# PIC32MK0128MCA028 register map
Vendor: Microchip
Registers are 32-bit, read-write, reset 0x0 unless marked. A register's access mark holds for its fields unless they carry their own. Addresses are absolute, and some are shared; only a register's first bit layout is shown; [hi:lo] are bit positions; {n}, {i} and the like mark numbered series.

## UART1
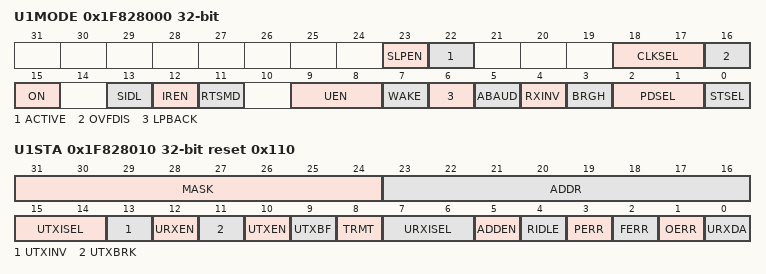
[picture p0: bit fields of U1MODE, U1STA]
0x1F828000 U1MODE
  [23] SLPEN, [22] ACTIVE, [18:17] CLKSEL, [16] OVFDIS, [15] ON, [13] SIDL, [12] IREN, [11] RTSMD, [9:8] UEN, [7] WAKE, [6] LPBACK, [5] ABAUD, [4] RXINV, [3] BRGH, [2:1] PDSEL, [0] STSEL
0x1F828010 U1STA reset 0x110
  [31:24] MASK
  [23:16] ADDR
  [15:14] UTXISEL
  [13] UTXINV
  [12] URXEN
  [11] UTXBRK
  [10] UTXEN
  [9] UTXBF ro
  [8] TRMT ro
  [7:6] URXISEL
  [5] ADDEN
  [4] RIDLE ro
  [3] PERR ro
  [2] FERR ro
  [1] OERR — (can only be cleared)
  [0] URXDA ro
0x1F828020 U1TXREG
  [8:0] U1TXREG
0x1F828030 U1RXREG ro
  [8:0] U1RXREG
0x1F828040 U1BRG
  [19:0] BRG

## UART2
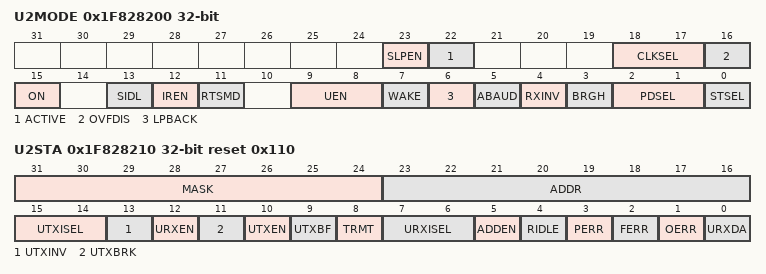
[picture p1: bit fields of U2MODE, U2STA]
0x1F828200 U2MODE
  [23] SLPEN, [22] ACTIVE, [18:17] CLKSEL, [16] OVFDIS, [15] ON, [13] SIDL, [12] IREN, [11] RTSMD, [9:8] UEN, [7] WAKE, [6] LPBACK, [5] ABAUD, [4] RXINV, [3] BRGH, [2:1] PDSEL, [0] STSEL
0x1F828210 U2STA reset 0x110
  [31:24] MASK
  [23:16] ADDR
  [15:14] UTXISEL
  [13] UTXINV
  [12] URXEN
  [11] UTXBRK
  [10] UTXEN
  [9] UTXBF ro
  [8] TRMT ro
  [7:6] URXISEL
  [5] ADDEN
  [4] RIDLE ro
  [3] PERR ro
  [2] FERR ro
  [1] OERR — (can only be cleared)
  [0] URXDA ro
0x1F828220 U2TXREG
  [8:0] U2TXREG
0x1F828230 U2RXREG ro
  [8:0] U2RXREG
0x1F828240 U2BRG
  [19:0] BRG

## MCPWMMODULE
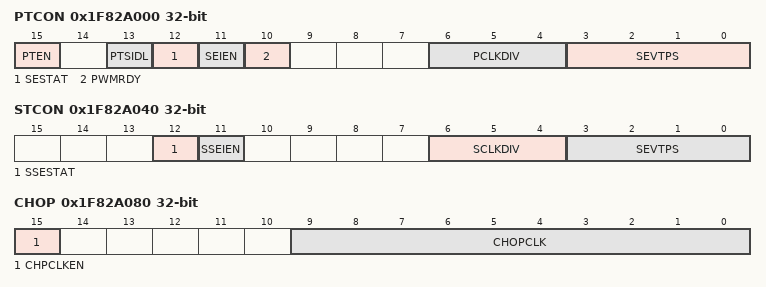
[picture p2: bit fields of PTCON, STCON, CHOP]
0x1F82A000 PTCON
  [15] PTEN, [13] PTSIDL, [12] SESTAT, [11] SEIEN, [10] PWMRDY, [6:4] PCLKDIV, [3:0] SEVTPS
0x1F82A010 PTPER
  [15:0] PTPER
0x1F82A020 SEVTCMP
  [15:0] SEVTCMP
0x1F82A030 PMTMR
  [15:0] PMTMR
0x1F82A040 STCON
  [12] SSESTAT, [11] SSEIEN, [6:4] SCLKDIV, [3:0] SEVTPS
0x1F82A050 STPER
  [15:0] STPER
0x1F82A060 SSEVTCMP
  [15:0] SSEVTCMP
0x1F82A070 SMTMR
  [15:0] SMTMR
0x1F82A080 CHOP
  [15] CHPCLKEN, [9:0] CHOPCLK
0x1F82A090 PWMKEY
  [15:0] PWMKEY

## MCPWMCHANNEL
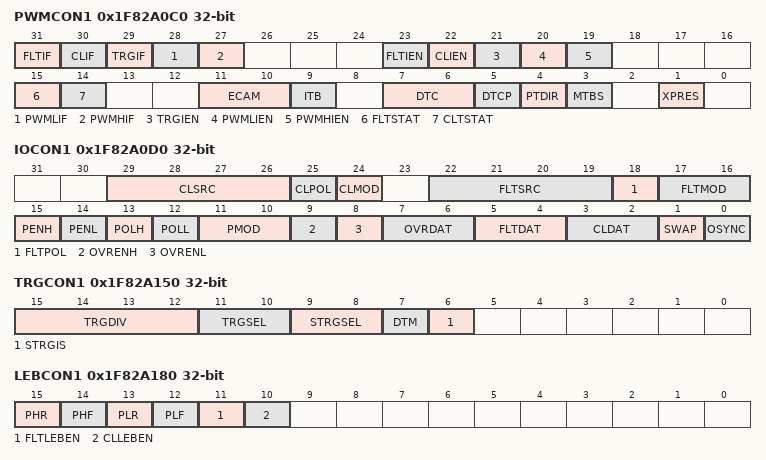
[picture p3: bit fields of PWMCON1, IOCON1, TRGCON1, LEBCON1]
0x1F82A0C0 PWMCON1
  [31] FLTIF, [30] CLIF, [29] TRGIF, [28] PWMLIF, [27] PWMHIF, [23] FLTIEN, [22] CLIEN, [21] TRGIEN, [20] PWMLIEN, [19] PWMHIEN, [15] FLTSTAT, [14] CLTSTAT, [11:10] ECAM, [9] ITB, [7:6] DTC, [5] DTCP, [4] PTDIR, [3] MTBS, [1] XPRES
0x1F82A0D0 IOCON1
  [29:26] CLSRC, [25] CLPOL, [24] CLMOD, [22:19] FLTSRC, [18] FLTPOL, [17:16] FLTMOD, [15] PENH, [14] PENL, [13] POLH, [12] POLL, [11:10] PMOD, [9] OVRENH, [8] OVRENL, [7:6] OVRDAT, [5:4] FLTDAT, [3:2] CLDAT, [1] SWAP, [0] OSYNC
0x1F82A0E0 PDC1
  [15:0] PDC
0x1F82A0F0 SDC1
  [15:0] SDC
0x1F82A100 PHASE1
  [15:0] PHASE
0x1F82A110 DTR1
  [15:0] DTR
0x1F82A120 ALTDTR1
  [15:0] ALTDTR
0x1F82A130 DTCOMP1
  [13:0] COMP
0x1F82A140 TRIG1
  [15:0] TRGCMP
0x1F82A150 TRGCON1
  [15:12] TRGDIV, [11:10] TRGSEL, [9:8] STRGSEL, [7] DTM, [6] STRGIS
0x1F82A160 STRIG1
  [15:0] STRGCMP
0x1F82A170 CAP1
  [15:0] CAP
0x1F82A180 LEBCON1
  [15] PHR, [14] PHF, [13] PLR, [12] PLF, [11] FLTLEBEN, [10] CLLEBEN
0x1F82A190 LEBDLY1
  [11:0] LEB
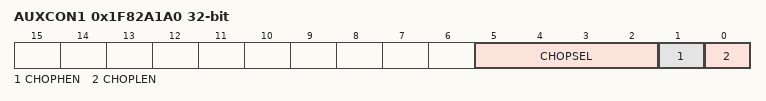
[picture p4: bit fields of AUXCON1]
0x1F82A1A0 AUXCON1
  [5:2] CHOPSEL, [1] CHOPHEN, [0] CHOPLEN
0x1F82A1B0 PTMR1
  [15:0] TMR

## pwm_mc_upb
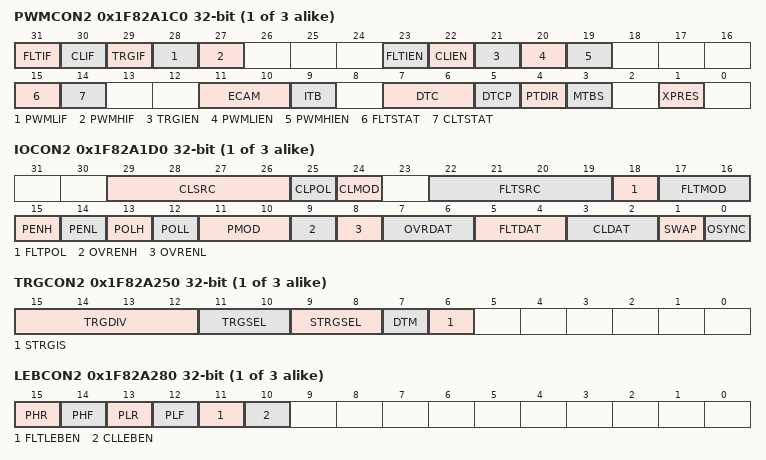
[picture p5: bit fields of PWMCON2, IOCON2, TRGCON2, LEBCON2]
{0x1F829FC0+0x100*i} PWMCON{i} (i=2..4)
  [31] FLTIF, [30] CLIF, [29] TRGIF, [28] PWMLIF, [27] PWMHIF, [23] FLTIEN, [22] CLIEN, [21] TRGIEN, [20] PWMLIEN, [19] PWMHIEN, [15] FLTSTAT, [14] CLTSTAT, [11:10] ECAM, [9] ITB, [7:6] DTC, [5] DTCP, [4] PTDIR, [3] MTBS, [1] XPRES
{0x1F829FD0+0x100*i} IOCON{i} (i=2..4)
  [29:26] CLSRC, [25] CLPOL, [24] CLMOD, [22:19] FLTSRC, [18] FLTPOL, [17:16] FLTMOD, [15] PENH, [14] PENL, [13] POLH, [12] POLL, [11:10] PMOD, [9] OVRENH, [8] OVRENL, [7:6] OVRDAT, [5:4] FLTDAT, [3:2] CLDAT, [1] SWAP, [0] OSYNC
{0x1F829FE0+0x100*i} PDC{i} (i=2..4)
  [15:0] PDC
{0x1F829FF0+0x100*i} SDC{i} (i=2..4)
  [15:0] SDC
{0x1F82A000+0x100*i} PHASE{i} (i=2..4)
  [15:0] PHASE
{0x1F82A010+0x100*i} DTR{i} (i=2..4)
  [15:0] DTR
{0x1F82A020+0x100*i} ALTDTR{i} (i=2..4)
  [15:0] ALTDTR
{0x1F82A030+0x100*i} DTCOMP{i} (i=2..4)
  [13:0] COMP
{0x1F82A040+0x100*i} TRIG{i} (i=2..4)
  [15:0] TRGCMP
{0x1F82A050+0x100*i} TRGCON{i} (i=2..4)
  [15:12] TRGDIV, [11:10] TRGSEL, [9:8] STRGSEL, [7] DTM, [6] STRGIS
{0x1F82A060+0x100*i} STRIG{i} (i=2..4)
  [15:0] STRGCMP
{0x1F82A070+0x100*i} CAP{i} (i=2..4)
  [15:0] CAP
{0x1F82A080+0x100*i} LEBCON{i} (i=2..4)
  [15] PHR, [14] PHF, [13] PLR, [12] PLF, [11] FLTLEBEN, [10] CLLEBEN
{0x1F82A090+0x100*i} LEBDLY{i} (i=2..4)
  [11:0] LEB
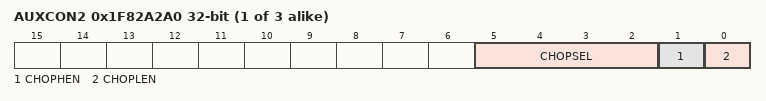
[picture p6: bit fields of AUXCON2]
{0x1F82A0A0+0x100*i} AUXCON{i} (i=2..4)
  [5:2] CHOPSEL, [1] CHOPHEN, [0] CHOPLEN
{0x1F82A0B0+0x100*i} PTMR{i} (i=2..4)
  [15:0] TMR
